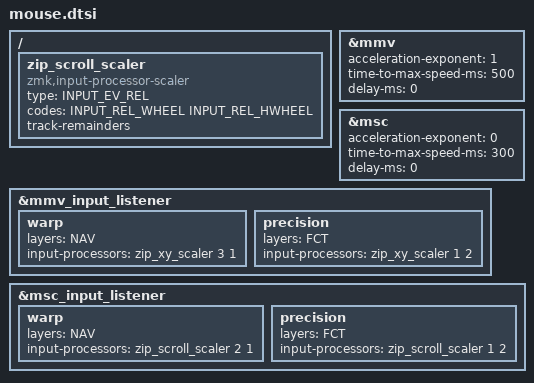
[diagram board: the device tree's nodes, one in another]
// Settings tuned for 3840 x 2160 display resolution
#define ZMK_POINTING_DEFAULT_MOVE_VAL 600 // 600
#define ZMK_POINTING_DEFAULT_SCRL_VAL 20  // 10

#include <dt-bindings/zmk/pointing.h>
#include <input/processors.dtsi>
#include <zephyr/dt-bindings/input/input-event-codes.h>

// Layer indexes — must stay in sync with corne.keymap.
// Defined defensively here in case this file is included before the keymap's
// own #defines (as is the case in corne.keymap today).
#ifndef DEF
#define DEF 0
#endif
#ifndef SYM
#define SYM 1
#endif
#ifndef NUM
#define NUM 2
#endif
#ifndef NAV
#define NAV 3
#endif
#ifndef FCT
#define FCT 4
#endif
#ifndef PTR
#define PTR 5
#endif
#ifndef SYS
#define SYS 6
#endif

// Based on @caksoylar's config, defaults in comments
&mmv {
  acceleration-exponent = <1>;          // 1
  time-to-max-speed-ms = <500>;         // 300
  delay-ms = <0>;                       // 0
};

&msc {
  acceleration-exponent = <0>;          // 0
  time-to-max-speed-ms = <300>;         // 300
  delay-ms = <0>;                       // 0
};

&mmv_input_listener {
  warp {
    layers = <NAV>;
    input-processors = <&zip_xy_scaler 3 1>;
  };
  precision {
    layers = <FCT>;
    input-processors = <&zip_xy_scaler 1 2>;
  };
};

/ {
  zip_scroll_scaler: zip_scroll_scaler {
    compatible = "zmk,input-processor-scaler";
    #input-processor-cells = <2>;
    type = <INPUT_EV_REL>;
    codes = <INPUT_REL_WHEEL INPUT_REL_HWHEEL>;
    track-remainders;
  };
};

&msc_input_listener {
  warp {
    layers = <NAV>;
    input-processors = <&zip_scroll_scaler 2 1>;
  };
  precision {
    layers = <FCT>;
    input-processors = <&zip_scroll_scaler 1 2>;
  };
};

#define U_MS_U &mmv MOVE_UP
#define U_MS_D &mmv MOVE_DOWN
#define U_MS_L &mmv MOVE_LEFT
#define U_MS_R &mmv MOVE_RIGHT
#define U_WH_U &msc SCRL_UP
#define U_WH_D &msc SCRL_DOWN
#define U_WH_L &msc SCRL_LEFT
#define U_WH_R &msc SCRL_RIGHT
